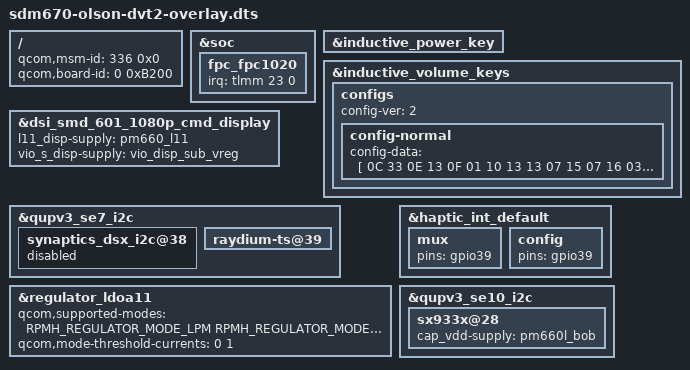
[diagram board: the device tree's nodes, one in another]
/* Copyright (c) 2018, The Linux Foundation. All rights reserved.
 *
 * This program is free software; you can redistribute it and/or modify
 * it under the terms of the GNU General Public License version 2 and
 * only version 2 as published by the Free Software Foundation.
 *
 * This program is distributed in the hope that it will be useful,
 * but WITHOUT ANY WARRANTY; without even the implied warranty of
 * MERCHANTABILITY or FITNESS FOR A PARTICULAR PURPOSE.  See the
 * GNU General Public License for more details.
 */

/dts-v1/;
/plugin/;

#include "sdm710-olson-common-overlay.dtsi"

/ {
	qcom,msm-id = <336 0x0>;
	qcom,board-id = <0 0xB200>;
};

/*
 * Olson HW rev DVT2 specific changes go here
 */
&soc {
	fpc_fpc1020 {
		irq = <&tlmm 23 0>;
	};
};

&inductive_power_key {
	status = "ok";
};

&inductive_volume_keys {
	status = "ok";
	configs {
		config-ver = <2>;
		config-normal {
			config-data = [
				0C 33 /*EN*/
				0E 13 /*GAIN0*/
				0F 01 /*LP_SCAN_RATE*/
				10 13 /*GAIN1*/
				13 07 /*LP_BASE_INC*/
				15 07 /*NP_BASE_INC*/
				16 03 /*BTPAUSE_MAXWIN*/
				20 59 /*SENSOR0_CFG*/
				22 59 /*SENSOR1_CFG*/
			];
		};
	};
};

&dsi_smd_601_1080p_cmd_display {
	l11_disp-supply = <&pm660_l11>;
	vio_s_disp-supply = <&vio_disp_sub_vreg>;
};

&qupv3_se7_i2c {
	synaptics_dsx_i2c@38 {
		status = "/chosen","mmi,cli","true";
	};
	raydium-ts@39 {
		status = "ok";
	};
};

&regulator_ldoa11 {
	/* allow NPM */
	qcom,supported-modes =
			<RPMH_REGULATOR_MODE_LPM
			 RPMH_REGULATOR_MODE_HPM>;
	qcom,mode-threshold-currents = <0 1>;
};

&haptic_int_default {
	mux {
		pins = "gpio39";
	};

	config {
		pins = "gpio39";
	};
};

&qupv3_se10_i2c {
	sx933x@28 {
		cap_vdd-supply = <&pm660l_bob>;
	};
};
